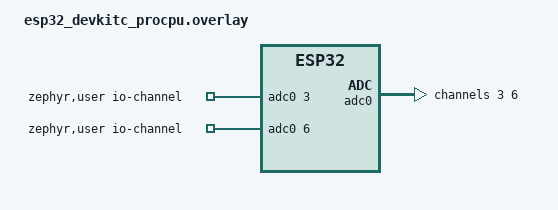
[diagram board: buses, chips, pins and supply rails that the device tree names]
/*
 * Copyright (c) 2026 Espressif Systems (Shanghai) Co., Ltd.
 *
 * SPDX-License-Identifier: Apache-2.0
 */

/ {
	aliases {
		adc0 = &adc0;
	};

	zephyr,user {
		io-channels = <&adc0 3>, <&adc0 6>;
	};
};

&adc0 {
	status = "okay";
	#address-cells = <1>;
	#size-cells = <0>;

	channel@3 {
		reg = <3>;
		zephyr,gain = "ADC_GAIN_1_4";
		zephyr,reference = "ADC_REF_INTERNAL";
		zephyr,acquisition-time = <ADC_ACQ_TIME_DEFAULT>;
		zephyr,resolution = <12>;
	};

	channel@6 {
		reg = <6>;
		zephyr,gain = "ADC_GAIN_1_4";
		zephyr,reference = "ADC_REF_INTERNAL";
		zephyr,acquisition-time = <ADC_ACQ_TIME_DEFAULT>;
		zephyr,resolution = <12>;
	};
};
